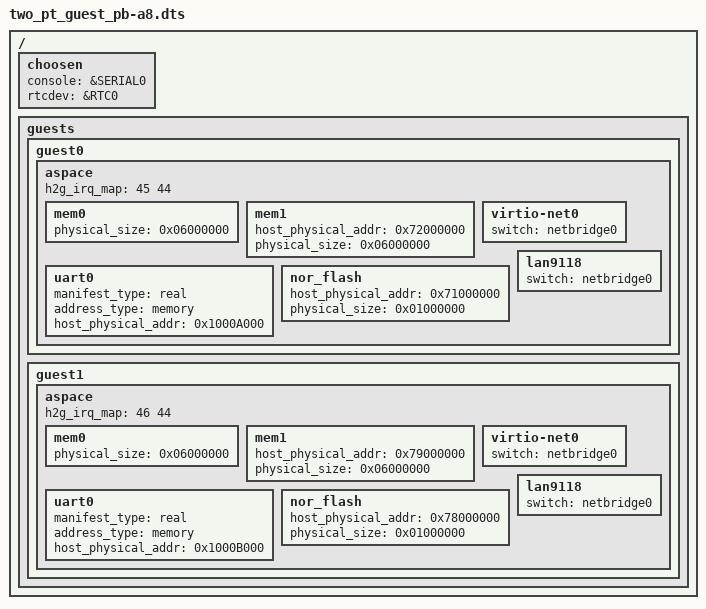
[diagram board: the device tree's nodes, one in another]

/dts-v1/;

/include/ "pb-a8.dtsi"

/include/ "../../common/guests/two_guest_pb-a8.dtsi"

/ {
	choosen {
		console = &SERIAL0;
		rtcdev = &RTC0;
	};

	guests {
		guest0 {
			aspace {
				/* Pass through device access requires 
				 * host IRQ to guest IRQ routing
				 */
				h2g_irq_map = </* Host => Guest */
						  /* uart0 */
						   45      44 
					      >;

				mem0 {
					physical_size = <0x06000000>; /* 96 MB */
				};

				mem1 {
					host_physical_addr = <0x72000000>;
					physical_size = <0x06000000>; /* 96 MB */
				};

				/* Pass Through Device PL011 */
				uart0 {
					manifest_type = "real";
					address_type = "memory";
					host_physical_addr = <0x1000A000>;
					device_type = "serial";
				};

				virtio-net0 {
					switch = "netbridge0";
				};

				nor_flash {
					host_physical_addr = <0x71000000>;
					physical_size = <0x01000000>; /* 16 MB */
				};

				lan9118 {
					switch = "netbridge0";
				};
			};
		};

		guest1 {
			aspace {
				/* Pass through device access requires 
				 * host IRQ to guest IRQ routing
				 */
				h2g_irq_map = </* Host => Guest */
						  /* uart0 */
						   46      44 
					      >;

				mem0 {
					physical_size = <0x06000000>; /* 96 MB */
				};

				mem1 {
					host_physical_addr = <0x79000000>;
					physical_size = <0x06000000>; /* 96 MB */
				};

				/* Pass Through Device PL011 */
				uart0 {
					manifest_type = "real";
					address_type = "memory";
					host_physical_addr = <0x1000B000>;
					device_type = "serial";
				};

				virtio-net0 {
					switch = "netbridge0";
				};

				nor_flash {
					host_physical_addr = <0x78000000>;
					physical_size = <0x01000000>; /* 16 MB */
				};

				lan9118 {
					switch = "netbridge0";
				};
			};
		};
	};
};
